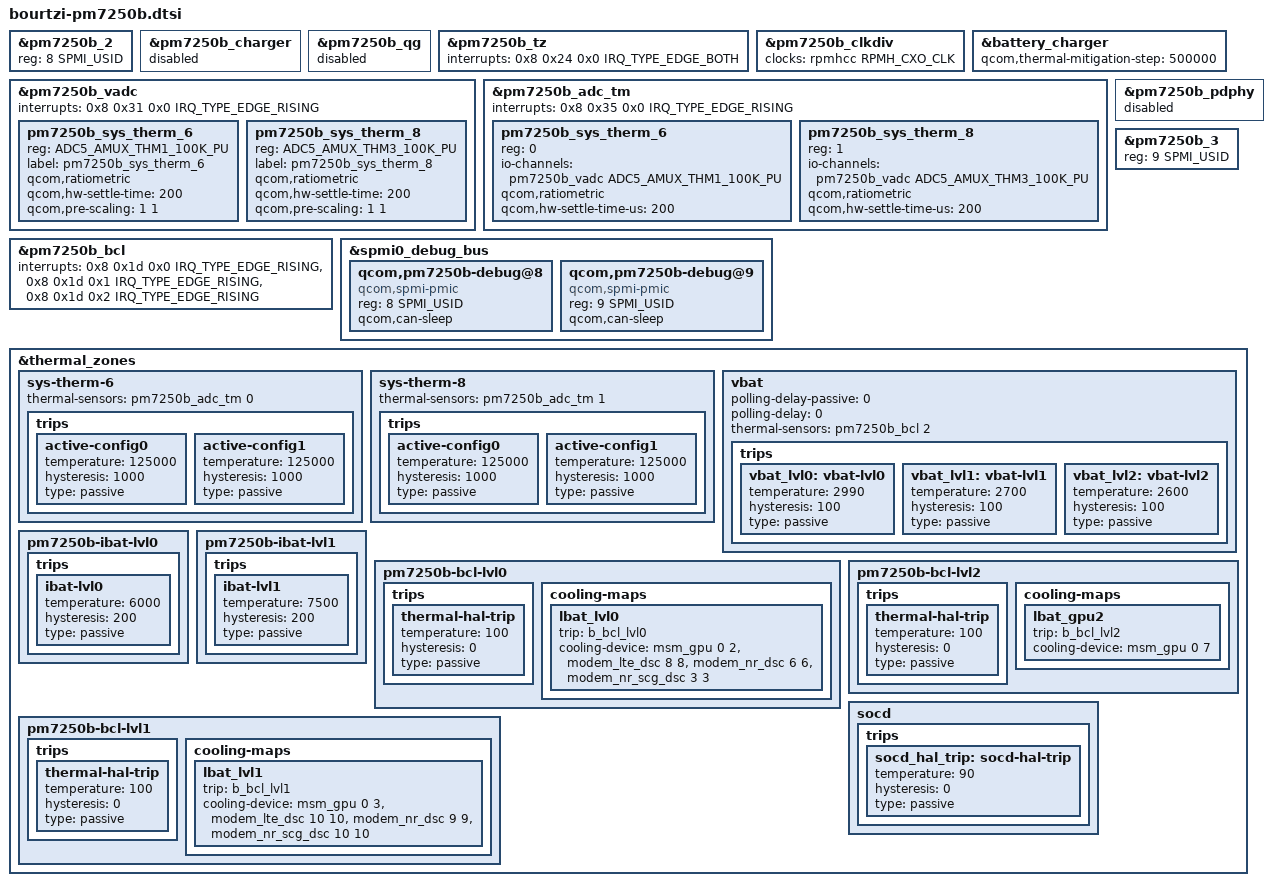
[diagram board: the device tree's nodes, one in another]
// SPDX-License-Identifier: BSD-3-Clause
/*
 * Copyright (c) Qualcomm Technologies, Inc. and/or its subsidiaries.
 */

#include "pm7250b.dtsi"
#include <dt-bindings/clock/qcom,rpmh.h>
#include <dt-bindings/thermal/thermal.h>

&pm7250b_2 {
	reg = <8 SPMI_USID>;
};

&pm7250b_charger {
	status = "disabled";
};

&pm7250b_qg {
	status = "disabled";
};

&pm7250b_tz {
	interrupts = <0x8 0x24 0x0 IRQ_TYPE_EDGE_BOTH>;
};

&pm7250b_clkdiv {
	clocks = <&rpmhcc RPMH_CXO_CLK>;
};

&battery_charger {
	#cooling-cells = <2>;
	qcom,thermal-mitigation-step = <500000>;
};

&pm7250b_vadc {
	interrupts = <0x8 0x31 0x0 IRQ_TYPE_EDGE_RISING>;

	pm7250b_sys_therm_6 {
		reg = <ADC5_AMUX_THM1_100K_PU>;
		label = "pm7250b_sys_therm_6";
		qcom,ratiometric;
		qcom,hw-settle-time = <200>;
		qcom,pre-scaling = <1 1>;
	};

	pm7250b_sys_therm_8 {
		reg = <ADC5_AMUX_THM3_100K_PU>;
		label = "pm7250b_sys_therm_8";
		qcom,ratiometric;
		qcom,hw-settle-time = <200>;
		qcom,pre-scaling = <1 1>;
	};
};

&pm7250b_adc_tm {
	interrupts = <0x8 0x35 0x0 IRQ_TYPE_EDGE_RISING>;

	pm7250b_sys_therm_6 {
		reg = <0>;
		io-channels = <&pm7250b_vadc ADC5_AMUX_THM1_100K_PU>;
		qcom,ratiometric;
		qcom,hw-settle-time-us = <200>;
	};

	pm7250b_sys_therm_8 {
		reg = <1>;
		io-channels = <&pm7250b_vadc ADC5_AMUX_THM3_100K_PU>;
		qcom,ratiometric;
		qcom,hw-settle-time-us = <200>;
	};
};

&pm7250b_bcl {
	interrupts = <0x8 0x1d 0x0 IRQ_TYPE_EDGE_RISING>,
		     <0x8 0x1d 0x1 IRQ_TYPE_EDGE_RISING>,
		     <0x8 0x1d 0x2 IRQ_TYPE_EDGE_RISING>;
};

&pm7250b_pdphy {
	status = "disabled";
};

&pm7250b_3 {
	reg = <9 SPMI_USID>;
};

&spmi0_debug_bus {
	qcom,pm7250b-debug@8 {
		compatible = "qcom,spmi-pmic";
		reg = <8 SPMI_USID>;
		#address-cells = <2>;
		#size-cells = <0>;
		qcom,can-sleep;
	};

	qcom,pm7250b-debug@9 {
		compatible = "qcom,spmi-pmic";
		reg = <9 SPMI_USID>;
		#address-cells = <2>;
		#size-cells = <0>;
		qcom,can-sleep;
	};
};

&thermal_zones {
	sys-therm-6 {
		thermal-sensors = <&pm7250b_adc_tm 0>;

		trips {
			active-config0 {
				temperature = <125000>;
				hysteresis = <1000>;
				type = "passive";
			};

			active-config1 {
				temperature = <125000>;
				hysteresis = <1000>;
				type = "passive";
			};
		};
	};

	sys-therm-8 {
		thermal-sensors = <&pm7250b_adc_tm 1>;

		trips {
			active-config0 {
				temperature = <125000>;
				hysteresis = <1000>;
				type = "passive";
			};

			active-config1 {
				temperature = <125000>;
				hysteresis = <1000>;
				type = "passive";
			};
		};
	};

	vbat {
		polling-delay-passive = <0>;
		polling-delay = <0>;
		thermal-sensors = <&pm7250b_bcl 2>;

		trips {
			vbat_lvl0:vbat-lvl0 {
				temperature = <2990>;
				hysteresis = <100>;
				type = "passive";
			};

			vbat_lvl1:vbat-lvl1 {
				temperature = <2700>;
				hysteresis = <100>;
				type = "passive";
			};

			vbat_lvl2:vbat-lvl2 {
				temperature = <2600>;
				hysteresis = <100>;
				type = "passive";
			};
		};
	};

	pm7250b-ibat-lvl0 {
		trips {
			ibat-lvl0 {
				temperature = <6000>;
				hysteresis = <200>;
				type = "passive";
			};
		};
	};

	pm7250b-ibat-lvl1 {
		trips {
			ibat-lvl1 {
				temperature = <7500>;
				hysteresis = <200>;
				type = "passive";
			};
		};
	};

	pm7250b-bcl-lvl0 {
		trips {
			thermal-hal-trip {
				temperature = <100>;
				hysteresis = <0>;
				type = "passive";
			};
		};

		cooling-maps {
			lbat_lvl0 {
				trip = <&b_bcl_lvl0>;
				cooling-device = <&msm_gpu 0 2>,
						<&modem_lte_dsc 8 8>,
						<&modem_nr_dsc 6 6>,
						<&modem_nr_scg_dsc 3 3>;
			};
		};
	};

	pm7250b-bcl-lvl1 {
		trips {
			thermal-hal-trip {
				temperature = <100>;
				hysteresis = <0>;
				type = "passive";
			};
		};

		cooling-maps {
			lbat_lvl1 {
				trip = <&b_bcl_lvl1>;
				cooling-device = <&msm_gpu 0 3>,
						<&modem_lte_dsc 10 10>,
						<&modem_nr_dsc 9 9>,
						<&modem_nr_scg_dsc 10 10>;
			};
		};
	};

	pm7250b-bcl-lvl2 {
		trips {
			thermal-hal-trip {
				temperature = <100>;
				hysteresis = <0>;
				type = "passive";
			};
		};

		cooling-maps {
			lbat_gpu2 {
				trip = <&b_bcl_lvl2>;
				cooling-device = <&msm_gpu 0 7>;
			};
		};
	};

	socd {
		trips {
			socd_hal_trip:socd-hal-trip {
				temperature = <90>;
				hysteresis = <0>;
				type = "passive";
			};
		};
	};
};
